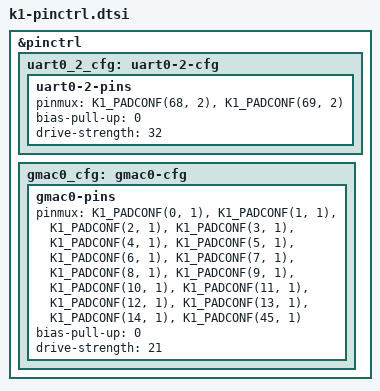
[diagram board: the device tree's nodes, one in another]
// SPDX-License-Identifier: GPL-2.0 OR MIT
/*
 * Copyright (c) 2024 Yixun Lan <dlan@gentoo.org>
 */

#include <dt-bindings/gpio/gpio.h>

#define K1_PADCONF(pin, func) (((pin) << 16) | (func))

&pinctrl {
	uart0_2_cfg: uart0-2-cfg {
		uart0-2-pins {
			pinmux = <K1_PADCONF(68, 2)>,
				 <K1_PADCONF(69, 2)>;

			bias-pull-up = <0>;
			drive-strength = <32>;
		};
	};

	gmac0_cfg: gmac0-cfg {
		gmac0-pins {
			pinmux = <K1_PADCONF(0, 1)>,
				 <K1_PADCONF(1, 1)>,
				 <K1_PADCONF(2, 1)>,
				 <K1_PADCONF(3, 1)>,
				 <K1_PADCONF(4, 1)>,
				 <K1_PADCONF(5, 1)>,
				 <K1_PADCONF(6, 1)>,
				 <K1_PADCONF(7, 1)>,
				 <K1_PADCONF(8, 1)>,
				 <K1_PADCONF(9, 1)>,
				 <K1_PADCONF(10, 1)>,
				 <K1_PADCONF(11, 1)>,
				 <K1_PADCONF(12, 1)>,
				 <K1_PADCONF(13, 1)>,
				 <K1_PADCONF(14, 1)>,
				 <K1_PADCONF(45, 1)>;

			bias-pull-up = <0>;
			drive-strength = <21>;
		};
	};
};
